# RL7005_IP_SVD register map
Vendor: Realtek
Registers are 32-bit, read-write, reset 0x0 unless marked. A register's access mark holds for its fields unless they carry their own. Offsets are from the block's base; [hi:lo] are bit positions; {n}, {i} and the like mark numbered series.

## PAGE3
Base 0x40000000
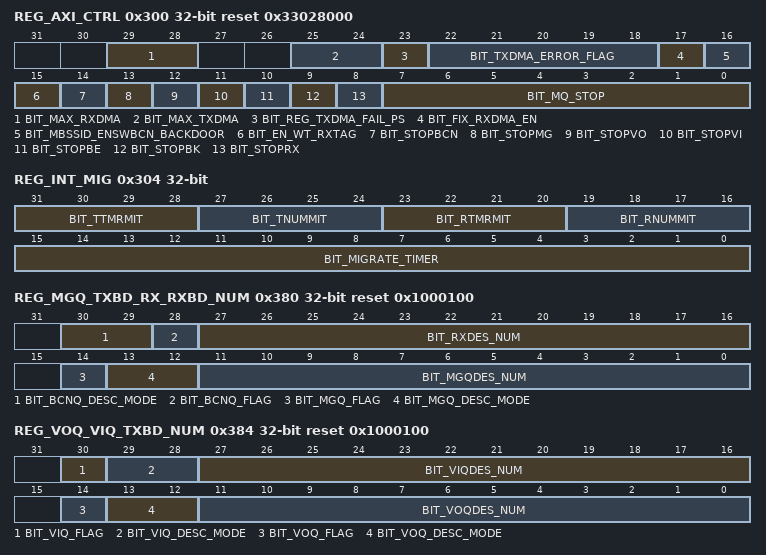
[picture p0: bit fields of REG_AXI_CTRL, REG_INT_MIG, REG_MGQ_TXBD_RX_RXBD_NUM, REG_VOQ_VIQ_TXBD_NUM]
0x300 REG_AXI_CTRL access per field reset 0x33028000
  [29:28] BIT_MAX_RXDMA rw — RXDMA Burst Size selection default 3. 0: 4bytes; 1: 16bytes; 2: 32bytes; 3: 64bytes
  [25:24] BIT_MAX_TXDMA rw — TXDMA Burst Size selection default 3. 0: 4bytes; 1: 16bytes; 2: 32bytes; 3: 64bytes.
  [23] BIT_REG_TXDMA_FAIL_PS wo — Write 1 to cause a txdma fail ps
  [22:18] BIT_TXDMA_ERROR_FLAG ro — {length_err,page_err,arb_err,prefetch_err,txqsel_err} length_err: txbd length and txdesc length unmatch page_err: txbd page num and txdesc page num unmatch arb_err: queue arb error prefetch_err: next queue arb error txqsel_err: tx queue select unmatch with txdesc queue select
  [17] BIT_FIX_RXDMA_EN rw — rxdma error fix enable
  [16] BIT_MBSSID_ENSWBCN_BACKDOOR rw — MBSSID enable software becon
  [15] BIT_EN_WT_RXTAG rw — Display Dword0[32:16] type of Rx buffer descriptor 0: TotalLen 1: Rxtag
  [14] BIT_STOPBCN rw — BCNQ DMA STOP
  [13] BIT_STOPMG rw — MGQ DMA STOP
  [12] BIT_STOPVO rw — VOQ DMA STOP
  [11] BIT_STOPVI rw — VIQ DMA STOP
  [10] BIT_STOPBE rw — BEQ DMA STOP
  [9] BIT_STOPBK rw — BKQ DMA STOP
  [8] BIT_STOPRX rw — RX DMA STOP
  [7:0] BIT_MQ_STOP rw — Stop MQ DMA
0x304 REG_INT_MIG
  [31:28] BIT_TTMRMIT — When the number of timer matched condition exceeds this setting, then interrupt is issued.
  [27:24] BIT_TNUMMIT — When the buffered TX packet number is matched, the interrupt is then issued
  [23:20] BIT_RTMRMIT — When the number of timer matched condition exceeds this setting, then interrupt is issued.
  [19:16] BIT_RNUMMIT — When the buffered RX packet number is matched, the interrupt is then issued
  [15:0] BIT_MIGRATE_TIMER — Timer for setting Interrupt Migration time, only use [2:0] 3'b000: 64 us 3'b001: 128 us 3'b010: 256 us 3'b011: 512 us 3'b100: 1024 us 3'b101: 2048 us 3'b110: 4096 us 3'b111: 8192 us
0x308 REG_BCNQ_TXBD_DESA
  [31:0] BIT_BPQDESA — Buffer Descriptor Base Address for Beacon Queue
0x310 REG_MGQ_TXBD_DESA
  [31:0] BIT_MGQDESA — Buffer Descriptor Base Address for Manage Queue
0x318 REG_VOQ_TXBD_DESA
  [31:0] BIT_VOQDESA — Buffer Descriptor Base Address for VO Queue
0x320 REG_VIQ_TXBD_DESA
  [31:0] BIT_VIQDESA — Buffer Descriptor Base Address for VI Queue
0x328 REG_BEQ_TXBD_DESA
  [31:0] BIT_BEQDESA — Buffer Descriptor Base Address for BE Queue
0x330 REG_BKQ_TXBD_DESA
  [31:0] BIT_BKQDESA — Buffer Descriptor Base Address for BK Queue
0x338 REG_RXQ_RXBD_DESA
  [31:0] BIT_RXNRML_DESA — Buffer Descriptor Base Address for RX
{0x340+8i} REG_MQ{i}_TXBD_DESA (i=0..7)
  [31:0] BIT_MQ{i}DESA — Buffer Descriptor Base Address for M{i} Queue
0x380 REG_MGQ_TXBD_RX_RXBD_NUM access per field reset 0x1000100
  [30:29] BIT_BCNQ_DESC_MODE rw — BCNQ descriptor mode : 0 : 2 segments each descriptor 1 : 4 segments each descriptor 2 : 8 segments each descriptor
  [28] BIT_BCNQ_FLAG rw — BCNQ FLAGing bit Read : BCNQ work Write : BCNQ Polling
  [27:16] BIT_RXDES_NUM rw — RX queue descriptor's number
  [14] BIT_MGQ_FLAG ro — MGQ FLAGing bit, read result will be bpqflag
  [13:12] BIT_MGQ_DESC_MODE rw — MGQ descriptor mode : 0 : 2 segments each descriptor 1 : 4 segments each descriptor 2 : 8 segments each descriptor
  [11:0] BIT_MGQDES_NUM rw — MG queue descriptor's number
0x384 REG_VOQ_VIQ_TXBD_NUM access per field reset 0x1000100
  [30] BIT_VIQ_FLAG ro — VIQ, read result will be viqflag
  [29:28] BIT_VIQ_DESC_MODE rw — VIQ descriptor mode : 0 : 2 segments each descriptor 1 : 4 segments each descriptor 2 : 8 segments each descriptor
  [27:16] BIT_VIQDES_NUM rw — VI queue descriptor's number
  [14] BIT_VOQ_FLAG ro — VOQ, read result will be voqflag
  [13:12] BIT_VOQ_DESC_MODE rw — VOQ descriptor mode : 0 : 2 segments each descriptor 1 : 4 segments each descriptor 2 : 8 segments each descriptor
  [11:0] BIT_VOQDES_NUM rw — VO queue descriptor's number
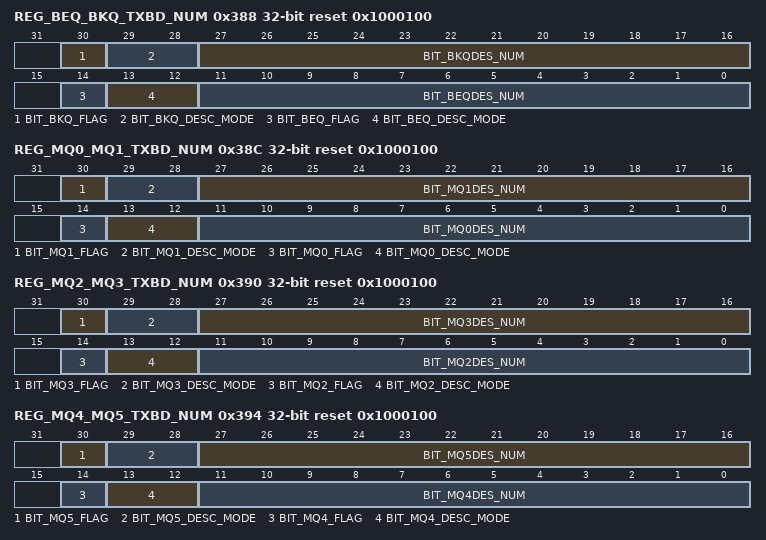
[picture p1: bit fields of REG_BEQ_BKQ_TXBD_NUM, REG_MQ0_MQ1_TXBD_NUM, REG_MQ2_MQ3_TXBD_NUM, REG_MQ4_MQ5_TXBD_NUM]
0x388 REG_BEQ_BKQ_TXBD_NUM access per field reset 0x1000100
  [30] BIT_BKQ_FLAG ro — BKQ, read result will be bkqflag
  [29:28] BIT_BKQ_DESC_MODE rw — BKQ descriptor mode : 0 : 2 segments each descriptor 1 : 4 segments each descriptor 2 : 8 segments each descriptor
  [27:16] BIT_BKQDES_NUM rw — BK queue descriptor's number
  [14] BIT_BEQ_FLAG ro — BEQ, read result will be beqflag
  [13:12] BIT_BEQ_DESC_MODE rw — BEQ descriptor mode : 0 : 2 segments each descriptor 1 : 4 segments each descriptor 2 : 8 segments each descriptor
  [11:0] BIT_BEQDES_NUM rw — BE queue descriptor's number
0x38C REG_MQ0_MQ1_TXBD_NUM access per field reset 0x1000100
  [30] BIT_MQ1_FLAG ro — MQ1, read result will be MQ1flag
  [29:28] BIT_MQ1_DESC_MODE rw — MQ1 descriptor mode : 0 : 2 segments each descriptor 1 : 4 segments each descriptor 2 : 8 segments each descriptor
  [27:16] BIT_MQ1DES_NUM rw — M1 queue descriptor's number
  [14] BIT_MQ0_FLAG ro — MQ0, read result will be MQ0flag
  [13:12] BIT_MQ0_DESC_MODE rw — MQ0 descriptor mode : 0 : 2 segments each descriptor 1 : 4 segments each descriptor 2 : 8 segments each descriptor
  [11:0] BIT_MQ0DES_NUM rw — M0 queue descriptor's number
0x390 REG_MQ2_MQ3_TXBD_NUM access per field reset 0x1000100
  [30] BIT_MQ3_FLAG ro — MQ3, read result will be MQ3flag
  [29:28] BIT_MQ3_DESC_MODE rw — MQ3 descriptor mode : 0 : 2 segments each descriptor 1 : 4 segments each descriptor 2 : 8 segments each descriptor
  [27:16] BIT_MQ3DES_NUM rw — M3 queue descriptor's number
  [14] BIT_MQ2_FLAG ro — MQ2, read result will be MQ2flag
  [13:12] BIT_MQ2_DESC_MODE rw — MQ2 descriptor mode : 0 : 2 segments each descriptor 1 : 4 segments each descriptor 2 : 8 segments each descriptor
  [11:0] BIT_MQ2DES_NUM rw — M2 queue descriptor's number
0x394 REG_MQ4_MQ5_TXBD_NUM access per field reset 0x1000100
  [30] BIT_MQ5_FLAG ro — MQ5, read result will be MQ5flag
  [29:28] BIT_MQ5_DESC_MODE rw — MQ5 descriptor mode : 0 : 2 segments each descriptor 1 : 4 segments each descriptor 2 : 8 segments each descriptor
  [27:16] BIT_MQ5DES_NUM rw — M5 queue descriptor's number
  [14] BIT_MQ4_FLAG ro — MQ4, read result will be MQ4flag
  [13:12] BIT_MQ4_DESC_MODE rw — MQ4 descriptor mode : 0 : 2 segments each descriptor 1 : 4 segments each descriptor 2 : 8 segments each descriptor
  [11:0] BIT_MQ4DES_NUM rw — M4 queue descriptor's number
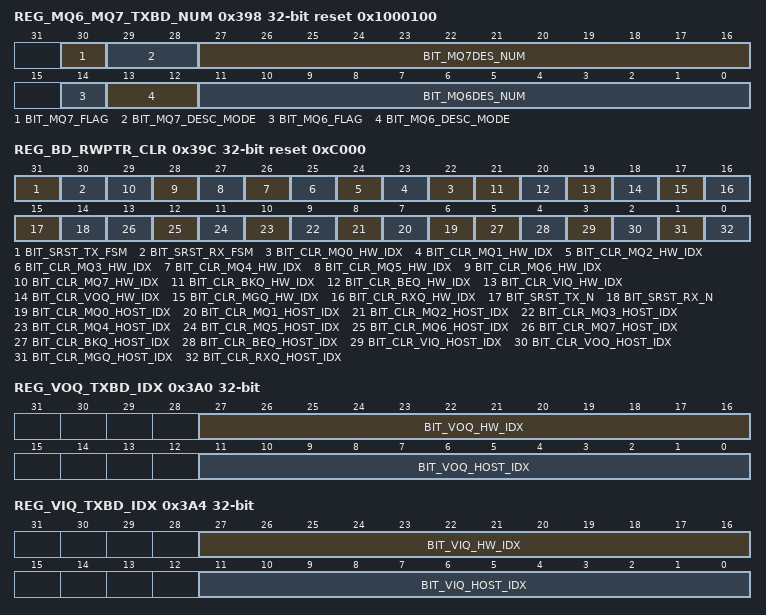
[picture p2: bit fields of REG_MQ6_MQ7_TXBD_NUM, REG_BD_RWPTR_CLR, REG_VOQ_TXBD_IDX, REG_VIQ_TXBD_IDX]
0x398 REG_MQ6_MQ7_TXBD_NUM access per field reset 0x1000100
  [30] BIT_MQ7_FLAG ro — MQ7, read result will be MQ7flag
  [29:28] BIT_MQ7_DESC_MODE rw — MQ7 descriptor mode : 0 : 2 segments each descriptor 1 : 4 segments each descriptor 2 : 8 segments each descriptor
  [27:16] BIT_MQ7DES_NUM rw — M7 queue descriptor's number
  [14] BIT_MQ6_FLAG ro — MQ6, read result will be MQ6flag
  [13:12] BIT_MQ6_DESC_MODE rw — MQ6 descriptor mode : 0 : 2 segments each descriptor 1 : 4 segments each descriptor 2 : 8 segments each descriptor
  [11:0] BIT_MQ6DES_NUM rw — M6 queue descriptor's number
0x39C REG_BD_RWPTR_CLR wo reset 0xC000
  [31] BIT_SRST_TX_FSM — Reset tx dma state
  [30] BIT_SRST_RX_FSM — Reset rx dma state
  [n+22] BIT_CLR_MQ{n}_HW_IDX (n=0..7) — Clear MQ{n} hardware index, write 1 and hardware auto clear
  [21] BIT_CLR_BKQ_HW_IDX — Clear BKQ hardware index, write 1 and hardware auto clear
  [20] BIT_CLR_BEQ_HW_IDX — Clear BEQ hardware index, write 1 and hardware auto clear
  [19] BIT_CLR_VIQ_HW_IDX — Clear VIQ hardware index, write 1 and hardware auto clear
  [18] BIT_CLR_VOQ_HW_IDX — Clear VOQ hardware index, write 1 and hardware auto clear
  [17] BIT_CLR_MGQ_HW_IDX — Clear MGQ hardware index, write 1 and hardware auto clear
  [16] BIT_CLR_RXQ_HW_IDX — Clear RXQ hardware index, write 1 and hardware auto clear
  [15] BIT_SRST_TX_N — Reset tx dma
  [14] BIT_SRST_RX_N — Reset rx dma
  [n+6] BIT_CLR_MQ{n}_HOST_IDX (n=0..7) — Clear MQ{n} host index, write 1 and hardware auto clear
  [5] BIT_CLR_BKQ_HOST_IDX — Clear MQ host index, write 1 and hardware auto clear
  [4] BIT_CLR_BEQ_HOST_IDX — Clear BEQ host index, write 1 and hardware auto clear
  [3] BIT_CLR_VIQ_HOST_IDX — Clear VIQ host index, write 1 and hardware auto clear
  [2] BIT_CLR_VOQ_HOST_IDX — Clear VOQ host index, write 1 and hardware auto clear
  [1] BIT_CLR_MGQ_HOST_IDX — Clear MGQ host index, write 1 and hardware auto clear
  [0] BIT_CLR_RXQ_HOST_IDX — Clear RXQ host index, write 1 and hardware auto clear
0x3A0 REG_VOQ_TXBD_IDX access per field
  [27:16] BIT_VOQ_HW_IDX ro — VO queue descriptor's hardware index
  [11:0] BIT_VOQ_HOST_IDX rw — VO queue descriptor's host index
0x3A4 REG_VIQ_TXBD_IDX access per field
  [27:16] BIT_VIQ_HW_IDX ro — VI queue descriptor's hardware index
  [11:0] BIT_VIQ_HOST_IDX rw — VI queue descriptor's host index
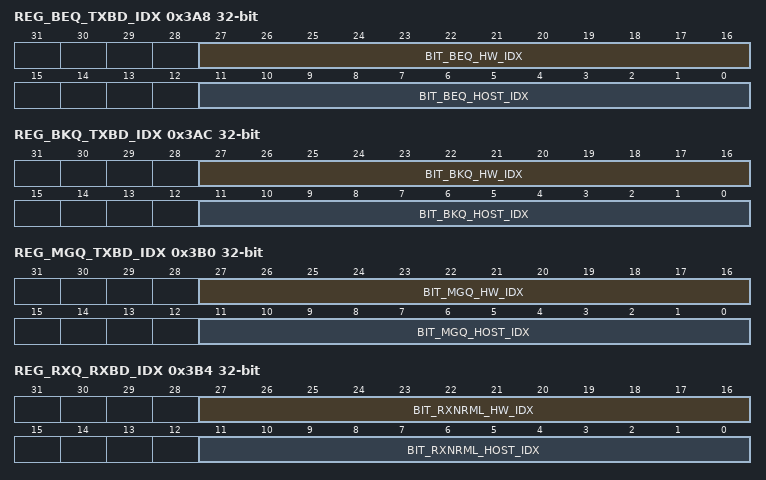
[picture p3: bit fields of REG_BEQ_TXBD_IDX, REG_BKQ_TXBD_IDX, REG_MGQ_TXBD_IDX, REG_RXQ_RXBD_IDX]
0x3A8 REG_BEQ_TXBD_IDX access per field
  [27:16] BIT_BEQ_HW_IDX ro — BE queue descriptor's hardware index
  [11:0] BIT_BEQ_HOST_IDX rw — BE queue descriptor's host index
0x3AC REG_BKQ_TXBD_IDX access per field
  [27:16] BIT_BKQ_HW_IDX ro — BK queue descriptor's hardware index
  [11:0] BIT_BKQ_HOST_IDX rw — BK queue descriptor's host index
0x3B0 REG_MGQ_TXBD_IDX access per field
  [27:16] BIT_MGQ_HW_IDX ro — MG queue descriptor's hardware index
  [11:0] BIT_MGQ_HOST_IDX rw — MG queue descriptor's host index
0x3B4 REG_RXQ_RXBD_IDX access per field
  [27:16] BIT_RXNRML_HW_IDX ro — RX queue descriptor's hardware index
  [11:0] BIT_RXNRML_HOST_IDX rw — RX queue descriptor's host index
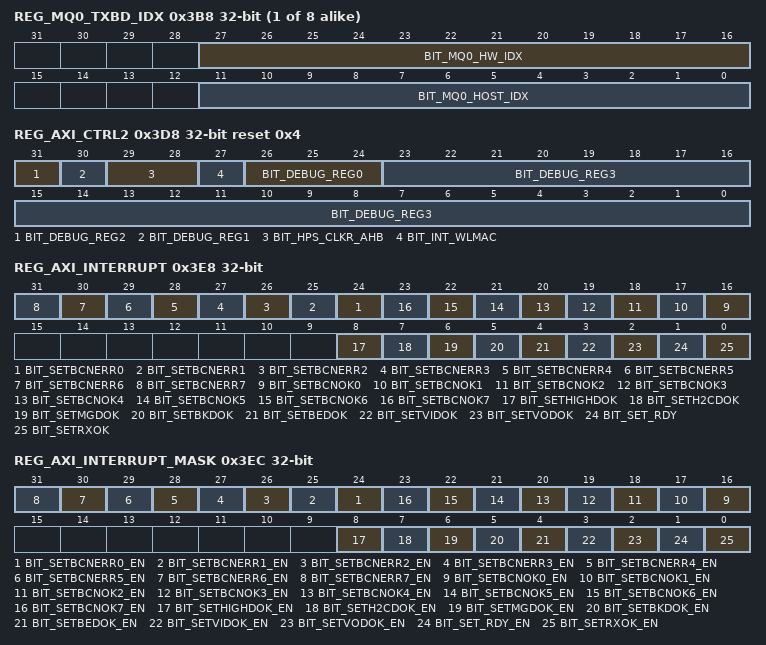
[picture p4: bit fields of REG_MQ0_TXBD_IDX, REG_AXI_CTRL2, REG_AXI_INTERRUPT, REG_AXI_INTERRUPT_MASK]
{0x3B8+4i} REG_MQ{i}_TXBD_IDX access per field (i=0..7)
  [27:16] BIT_MQ{i}_HW_IDX ro — MQ{i} queue descriptor's hardware index
  [11:0] BIT_MQ{i}_HOST_IDX rw — MQ{i} queue descriptor's host index
0x3D8 REG_AXI_CTRL2 reset 0x4
  [31] BIT_DEBUG_REG2 — Debug Selection Register
  [30] BIT_DEBUG_REG1 — Write:hps_clkr_ahb[3] Read:Debug Selection Register
  [29:28] BIT_HPS_CLKR_AHB — The Registers are used to prevent the deadlock whenever HW or FW turn off ANACLK or SYSCLK, which the HW or FW could not resume by themself. Currently they are not used in normal control flow. They might be helpful when Driver would like to handle whole Suspned & Resume flow by itself hps_clkr_ahb[2:1]
  [27] BIT_INT_WLMAC — Write:hps_clkr_ahb[0] Read:Interrupt.Write clear.
  [26:24] BIT_DEBUG_REG0 — Write:Debug Selection Register Read:3'b000
  [23:0] BIT_DEBUG_REG3 — Debug Selection Register
0x3E0 REG_DRVIER_TO_FIRMWARE_INFO
  [31:0] BIT_DRV2FW_AHB — DRIVER TO FIRMWARE MESSAGE
0x3E4 REG_FIRMWARE_TO_DRIVER_INFO ro
  [31:0] BIT_FW2DRV_AHB — FIRMWARE TO DRIVER MESSAGE
0x3E8 REG_AXI_INTERRUPT ro
  [n+24] BIT_SETBCNERR{n} (n=0..7) — setbcnderr{n}, beacon queue error, mbssid={n}
  [n+16] BIT_SETBCNOK{n} (n=0..7) — setbcndok{n}, beacon queue ok, mbssid={n}
  [8] BIT_SETHIGHDOK — sethighdok, high queue ok
  [7] BIT_SETH2CDOK — seth2cdok, h2c queue ok
  [6] BIT_SETMGDOK — setmgdok, manage queue ok
  [5] BIT_SETBKDOK — setbkdok, bk queue ok
  [4] BIT_SETBEDOK — setbedok, be queue ok
  [3] BIT_SETVIDOK — setvidok, vi queue ok
  [2] BIT_SETVODOK — setvodok, vo queue ok
  [1] BIT_SET_RDY — set_rdu, rx descriptor unavailable
  [0] BIT_SETRXOK — setrxok, rx dma ok
0x3EC REG_AXI_INTERRUPT_MASK
  [n+24] BIT_SETBCNERR{n}_EN (n=0..7) — setbcnderr{n}, beacon queue error, mbssid={n}
  [n+16] BIT_SETBCNOK{n}_EN (n=0..7) — setbcndok{n}, beacon queue ok, mbssid={n}
  [8] BIT_SETHIGHDOK_EN — sethighdok, high queue ok
  [7] BIT_SETH2CDOK_EN — seth2cdok, h2c queue ok
  [6] BIT_SETMGDOK_EN — setmgdok, manage queue ok
  [5] BIT_SETBKDOK_EN — setbkdok, bk queue ok
  [4] BIT_SETBEDOK_EN — setbedok, be queue ok
  [3] BIT_SETVIDOK_EN — setvidok, vi queue ok
  [2] BIT_SETVODOK_EN — setvodok, vo queue ok
  [1] BIT_SET_RDY_EN — set_rdu, rx descriptor unavailable
  [0] BIT_SETRXOK_EN — setrxok, rx dma ok
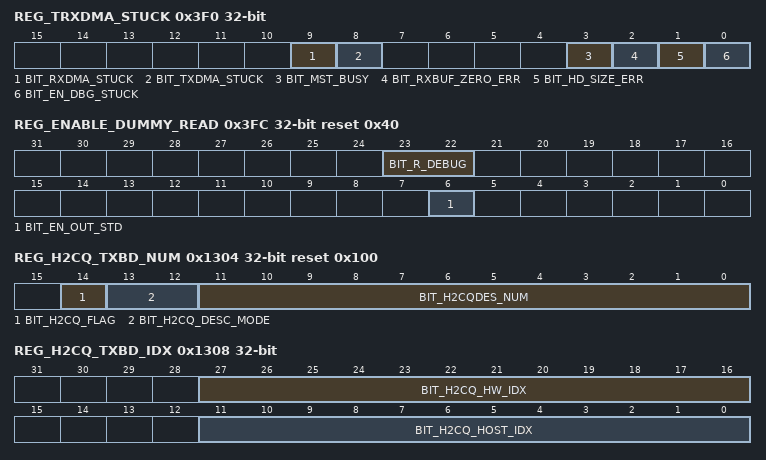
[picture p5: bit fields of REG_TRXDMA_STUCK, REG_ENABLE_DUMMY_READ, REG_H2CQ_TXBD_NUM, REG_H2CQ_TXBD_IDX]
0x3F0 REG_TRXDMA_STUCK access per field
  [9] BIT_RXDMA_STUCK ro — rx dma stuck
  [8] BIT_TXDMA_STUCK ro — tx dma stuck
  [3] BIT_MST_BUSY ro — axi master write/read busy
  [2] BIT_RXBUF_ZERO_ERR ro — rx pkt size equal to 0 when caculate buffer size
  [1] BIT_HD_SIZE_ERR ro — tx dma header size less than TXDESC_SIZE(40d)
  [0] BIT_EN_DBG_STUCK rw — enable trx dma stuck
0x3F4 REG_DUMMY_P3
  [31:0] dummy
0x3FC REG_ENABLE_DUMMY_READ wo reset 0x40
  [23:22] BIT_R_DEBUG — Debug Selection Register
  [6] BIT_EN_OUT_STD — cpl multi tag enable
0x1300 REG_H2CQ_TXBD_DESA
  [31:0] BIT_H2CQDESA — Buffer Descriptor Base Address for H2C Queue
0x1304 REG_H2CQ_TXBD_NUM access per field reset 0x100
  [14] BIT_H2CQ_FLAG ro — H2CQ, read result will be H2CQflag
  [13:12] BIT_H2CQ_DESC_MODE rw — H2CQ descriptor mode : 0 : 2 segments each descriptor 1 : 4 segments each descriptor 2 : 8 segments each descriptor
  [11:0] BIT_H2CQDES_NUM rw — H2C queue descriptor's number
0x1308 REG_H2CQ_TXBD_IDX access per field
  [27:16] BIT_H2CQ_HW_IDX ro — H2C queue descriptor's hardware index
  [11:0] BIT_H2CQ_HOST_IDX rw — H2C queue descriptor's host index
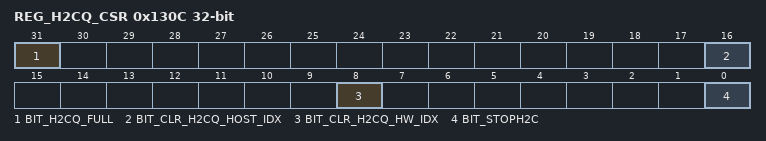
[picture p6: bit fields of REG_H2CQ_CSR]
0x130C REG_H2CQ_CSR access per field
  [31] BIT_H2CQ_FULL ro — Indicate H2CQ full. Write 1 to clear the bit.
  [16] BIT_CLR_H2CQ_HOST_IDX wo — Write 1 to clear H2CQ host index, and then hardware auto clear the bit
  [8] BIT_CLR_H2CQ_HW_IDX wo — Write 1 to clear H2CQ hardware index, and then hardware auto clear the bit
  [0] BIT_STOPH2C rw — Stop h2c queue dma
